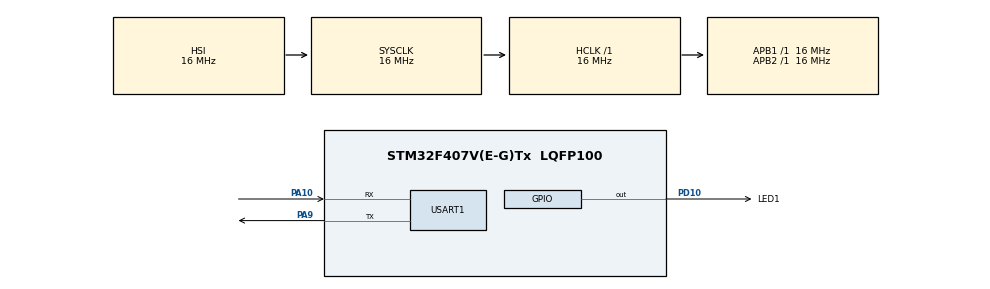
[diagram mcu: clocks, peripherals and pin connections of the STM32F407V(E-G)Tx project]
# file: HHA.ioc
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Dma.Request0=USART1_RX
Dma.USART1_RX.0.Direction=DMA_PERIPH_TO_MEMORY
Dma.USART1_RX.0.FIFOMode=DMA_FIFOMODE_DISABLE
Dma.USART1_RX.0.Instance=DMA2_Stream2
Dma.USART1_RX.0.MemDataAlignment=DMA_MDATAALIGN_BYTE
Dma.USART1_RX.0.MemInc=DMA_MINC_ENABLE
Dma.USART1_RX.0.Mode=DMA_CIRCULAR
Dma.USART1_RX.0.PeriphDataAlignment=DMA_PDATAALIGN_BYTE
Dma.USART1_RX.0.PeriphInc=DMA_PINC_DISABLE
Dma.USART1_RX.0.Priority=DMA_PRIORITY_HIGH
FREERTOS.Tasks01=defaultTask,0,128,StartDefaultTask,Default,NULL,Dynamic,NULL,NULL;LEDTask,-2,128,LEDTaskfunc,As weak,NULL,Static,LEDTaskBuffer,LEDTaskControlBlock
FREERTOS.configENABLE_FPU=1
Mcu.Family=STM32F4
Mcu.Name=STM32F407V(E-G)Tx
Mcu.Package=LQFP100
NVIC.DMA2_Stream2_IRQn=true\:5\:0\:false\:false\:true\:true\:false\:true\:true
NVIC.PriorityGroup=NVIC_PRIORITYGROUP_4
NVIC.TIM1_UP_TIM10_IRQn=true\:15\:0\:false\:false\:true\:false\:false\:true\:true
NVIC.TimeBase=TIM1_UP_TIM10_IRQn
NVIC.TimeBaseIP=TIM1
NVIC.USART1_IRQn=true\:5\:0\:false\:false\:true\:true\:true\:true\:true
PA10.Mode=Asynchronous
PA10.Signal=USART1_RX
PA13.Mode=Serial_Wire
PA13.Signal=SYS_JTMS-SWDIO
PA14.Mode=Serial_Wire
PA14.Signal=SYS_JTCK-SWCLK
PA9.Mode=Asynchronous
PA9.Signal=USART1_TX
PC14-OSC32_IN.Mode=LSE-External-Oscillator
PC14-OSC32_IN.Signal=RCC_OSC32_IN
PC15-OSC32_OUT.Mode=LSE-External-Oscillator
PC15-OSC32_OUT.Signal=RCC_OSC32_OUT
PD10.GPIO_Label=LED1
PD10.GPIO_Speed=GPIO_SPEED_FREQ_VERY_HIGH
PD10.Signal=GPIO_Output
PH0-OSC_IN.Mode=HSE-External-Oscillator
PH0-OSC_IN.Signal=RCC_OSC_IN
PH1-OSC_OUT.Mode=HSE-External-Oscillator
PH1-OSC_OUT.Signal=RCC_OSC_OUT
ProjectManager.HeapSize=0x200
ProjectManager.StackSize=0x400
ProjectManager.TargetToolchain=MDK-ARM V5.32
RCC.AHBFreq_Value=16000000
RCC.APB1Freq_Value=16000000
RCC.APB2Freq_Value=16000000
RCC.CortexFreq_Value=16000000
RCC.HSE_VALUE=25000000
RCC.HSI_VALUE=16000000
RCC.SYSCLKFreq_VALUE=16000000
RCC.VCOOutputFreq_Value=192000000
USART1.VirtualMode=VM_ASYNC
VP_FREERTOS_VS_CMSIS_V1.Mode=CMSIS_V1
VP_SYS_VS_tim1.Mode=TIM1
board=custom

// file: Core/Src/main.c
/* USER CODE BEGIN Header */
/**
  ******************************************************************************
  * @file           : main.c
  * @brief          : Main program body
  ******************************************************************************
  * @attention
  *
  * Copyright (c) 2025 STMicroelectronics.
  * All rights reserved.
  *
  * This software is licensed under terms that can be found in the LICENSE file
  * in the root directory of this software component.
  * If no LICENSE file comes with this software, it is provided AS-IS.
  *
  ******************************************************************************
  */
/* USER CODE END Header */
#include "main.h"
#include "cmsis_os.h"
#include "dma.h"
#include "usart.h"
#include "gpio.h"

void SystemClock_Config(void);
void MX_FREERTOS_Init(void);

int main(void)
{

  /* MCU Configuration--------------------------------------------------------*/

  /* Reset of all peripherals, Initializes the Flash interface and the Systick. */
  HAL_Init();

  /* Configure the system clock */
  SystemClock_Config();

  /* Initialize all configured peripherals */
  MX_GPIO_Init();
  MX_DMA_Init();
  MX_USART1_UART_Init();

  /* Call init function for freertos objects (in cmsis_os2.c) */
  MX_FREERTOS_Init();

  /* Start scheduler */
  osKernelStart();

  /* We should never get here as control is now taken by the scheduler */

  /* Infinite loop */
  while (1)
  {

  }
}

void SystemClock_Config(void)
{
  RCC_OscInitTypeDef RCC_OscInitStruct = {0};
  RCC_ClkInitTypeDef RCC_ClkInitStruct = {0};

  /** Configure the main internal regulator output voltage
  */
  __HAL_RCC_PWR_CLK_ENABLE();
  __HAL_PWR_VOLTAGESCALING_CONFIG(PWR_REGULATOR_VOLTAGE_SCALE1);

  /** Initializes the RCC Oscillators according to the specified parameters
  * in the RCC_OscInitTypeDef structure.
  */
  RCC_OscInitStruct.OscillatorType = RCC_OSCILLATORTYPE_HSI;
  RCC_OscInitStruct.HSIState = RCC_HSI_ON;
  RCC_OscInitStruct.HSICalibrationValue = RCC_HSICALIBRATION_DEFAULT;
  RCC_OscInitStruct.PLL.PLLState = RCC_PLL_NONE;
  if (HAL_RCC_OscConfig(&RCC_OscInitStruct) != HAL_OK)
  {
    Error_Handler();
  }

  /** Initializes the CPU, AHB and APB buses clocks
  */
  RCC_ClkInitStruct.ClockType = RCC_CLOCKTYPE_HCLK|RCC_CLOCKTYPE_SYSCLK
                              |RCC_CLOCKTYPE_PCLK1|RCC_CLOCKTYPE_PCLK2;
  RCC_ClkInitStruct.SYSCLKSource = RCC_SYSCLKSOURCE_HSI;
  RCC_ClkInitStruct.AHBCLKDivider = RCC_SYSCLK_DIV1;
  RCC_ClkInitStruct.APB1CLKDivider = RCC_HCLK_DIV1;
  RCC_ClkInitStruct.APB2CLKDivider = RCC_HCLK_DIV1;

  if (HAL_RCC_ClockConfig(&RCC_ClkInitStruct, FLASH_LATENCY_0) != HAL_OK)
  {
    Error_Handler();
  }
}

void HAL_TIM_PeriodElapsedCallback(TIM_HandleTypeDef *htim)
{
  if (htim->Instance == TIM1)
  {
    HAL_IncTick();
  }
}

void Error_Handler(void)
{
  __disable_irq();
  while (1)
  {
  }
}

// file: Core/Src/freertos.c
/* USER CODE BEGIN Header */
/**
  ******************************************************************************
  * File Name          : freertos.c
  * Description        : Code for freertos applications
  ******************************************************************************
  * @attention
  *
  * Copyright (c) 2025 STMicroelectronics.
  * All rights reserved.
  *
  * This software is licensed under terms that can be found in the LICENSE file
  * in the root directory of this software component.
  * If no LICENSE file comes with this software, it is provided AS-IS.
  *
  ******************************************************************************
  */
/* USER CODE END Header */

#include "FreeRTOS.h"
#include "task.h"
#include "main.h"
#include "cmsis_os.h"

/* USER CODE BEGIN Includes */
#include "usart.h"
/* USER CODE END Includes */

osThreadId defaultTaskHandle;
osThreadId LEDTaskHandle;
uint32_t LEDTaskBuffer[ 128 ];
osStaticThreadDef_t LEDTaskControlBlock;

void StartDefaultTask(void const * argument);
void LEDTaskfunc(void const * argument);

void MX_FREERTOS_Init(void); /* (MISRA C 2004 rule 8.1) */

/* GetIdleTaskMemory prototype (linked to static allocation support) */
void vApplicationGetIdleTaskMemory( StaticTask_t **ppxIdleTaskTCBBuffer, StackType_t **ppxIdleTaskStackBuffer, uint32_t *pulIdleTaskStackSize );

/* USER CODE BEGIN GET_IDLE_TASK_MEMORY */
static StaticTask_t xIdleTaskTCBBuffer;
static StackType_t xIdleStack[configMINIMAL_STACK_SIZE];

void vApplicationGetIdleTaskMemory( StaticTask_t **ppxIdleTaskTCBBuffer, StackType_t **ppxIdleTaskStackBuffer, uint32_t *pulIdleTaskStackSize )
{
  *ppxIdleTaskTCBBuffer = &xIdleTaskTCBBuffer;
  *ppxIdleTaskStackBuffer = &xIdleStack[0];
  *pulIdleTaskStackSize = configMINIMAL_STACK_SIZE;
  /* place for user code */
}
/* USER CODE END GET_IDLE_TASK_MEMORY */

void MX_FREERTOS_Init(void) {

  /* Create the thread(s) */
  /* definition and creation of defaultTask */
  osThreadDef(defaultTask, StartDefaultTask, osPriorityNormal, 0, 128);
  defaultTaskHandle = osThreadCreate(osThread(defaultTask), NULL);

  /* definition and creation of LEDTask */
  osThreadStaticDef(LEDTask, LEDTaskfunc, osPriorityLow, 0, 128, LEDTaskBuffer, &LEDTaskControlBlock);
  LEDTaskHandle = osThreadCreate(osThread(LEDTask), NULL);

}

void StartDefaultTask(void const * argument)
{
  for(;;)
  {
    osDelay(1);
  }
}

__weak void LEDTaskfunc(void const * argument)
{
  /* USER CODE BEGIN LEDTaskfunc */
  /* Infinite loop */
  for(;;)
  {
    osDelay(1000); // Delay for 1000 ms (1 second)
    // Toggle an LED (assuming an LED is connected to GPIO pin)
    HAL_GPIO_TogglePin(LED1_GPIO_Port, LED1_Pin); // Adjust GPIO port and pin as needed
    // You can add more functionality here, like sending a message or updating a variable
		HAL_UART_Transmit(&huart1, (uint8_t *)"LED Toggled\r\n", 14, HAL_MAX_DELAY); // Transmit message via UART

  }
  /* USER CODE END LEDTaskfunc */
}
